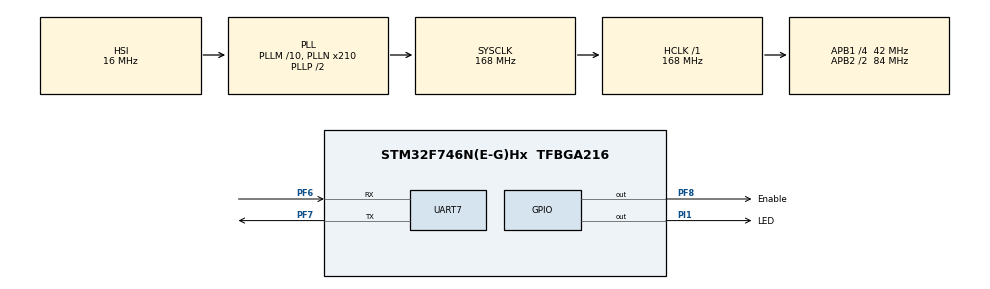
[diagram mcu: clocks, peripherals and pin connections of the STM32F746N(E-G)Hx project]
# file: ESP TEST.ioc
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Mcu.Family=STM32F7
Mcu.Name=STM32F746N(E-G)Hx
Mcu.Package=TFBGA216
NVIC.PriorityGroup=NVIC_PRIORITYGROUP_4
PF6.Mode=Asynchronous
PF6.Signal=UART7_RX
PF7.Mode=Asynchronous
PF7.Signal=UART7_TX
PF8.GPIO_Label=Enable
PF8.Signal=GPIO_Output
PI1.GPIO_Label=LED
PI1.Signal=GPIO_Output
ProjectManager.HeapSize=0x200
ProjectManager.StackSize=0x400
ProjectManager.TargetToolchain=SW4STM32
RCC.AHBFreq_Value=168000000
RCC.APB1CLKDivider=RCC_HCLK_DIV4
RCC.APB1Freq_Value=42000000
RCC.APB1TimFreq_Value=84000000
RCC.APB2CLKDivider=RCC_HCLK_DIV2
RCC.APB2Freq_Value=84000000
RCC.APB2TimFreq_Value=168000000
RCC.CortexFreq_Value=168000000
RCC.HCLKFreq_Value=168000000
RCC.HSE_VALUE=25000000
RCC.HSI_VALUE=16000000
RCC.LSE_VALUE=32768
RCC.PLLM=10
RCC.PLLN=210
RCC.PLLSourceVirtual=RCC_PLLSOURCE_HSI
RCC.SYSCLKFreq_VALUE=168000000
RCC.SYSCLKSource=RCC_SYSCLKSOURCE_PLLCLK
RCC.USBFreq_Value=168000000
RCC.VCOOutputFreq_Value=336000000
UART7.WordLength=UART_WORDLENGTH_8B
board=STM32F746G-DISCO

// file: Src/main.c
/**
  ******************************************************************************
  * File Name          : main.c
  * Description        : Main program body
  ******************************************************************************
  *
  * COPYRIGHT(c) 2016 STMicroelectronics
  *
  * Redistribution and use in source and binary forms, with or without modification,
  * are permitted provided that the following conditions are met:
  *   1. Redistributions of source code must retain the above copyright notice,
  *      this list of conditions and the following disclaimer.
  *   2. Redistributions in binary form must reproduce the above copyright notice,
  *      this list of conditions and the following disclaimer in the documentation
  *      and/or other materials provided with the distribution.
  *   3. Neither the name of STMicroelectronics nor the names of its contributors
  *      may be used to endorse or promote products derived from this software
  *      without specific prior written permission.
  *
  * THIS SOFTWARE IS PROVIDED BY THE COPYRIGHT HOLDERS AND CONTRIBUTORS "AS IS"
  * AND ANY EXPRESS OR IMPLIED WARRANTIES, INCLUDING, BUT NOT LIMITED TO, THE
  * IMPLIED WARRANTIES OF MERCHANTABILITY AND FITNESS FOR A PARTICULAR PURPOSE ARE
  * DISCLAIMED. IN NO EVENT SHALL THE COPYRIGHT HOLDER OR CONTRIBUTORS BE LIABLE
  * FOR ANY DIRECT, INDIRECT, INCIDENTAL, SPECIAL, EXEMPLARY, OR CONSEQUENTIAL
  * DAMAGES (INCLUDING, BUT NOT LIMITED TO, PROCUREMENT OF SUBSTITUTE GOODS OR
  * SERVICES; LOSS OF USE, DATA, OR PROFITS; OR BUSINESS INTERRUPTION) HOWEVER
  * CAUSED AND ON ANY THEORY OF LIABILITY, WHETHER IN CONTRACT, STRICT LIABILITY,
  * OR TORT (INCLUDING NEGLIGENCE OR OTHERWISE) ARISING IN ANY WAY OUT OF THE USE
  * OF THIS SOFTWARE, EVEN IF ADVISED OF THE POSSIBILITY OF SUCH DAMAGE.
  *
  ******************************************************************************
  */
#include "stm32f7xx_hal.h"

UART_HandleTypeDef huart7;

/* USER CODE BEGIN PV */
/* Private variables ---------------------------------------------------------*/

/* USER CODE END PV */

void SystemClock_Config(void);
void Error_Handler(void);
static void MX_GPIO_Init(void);
static void MX_UART7_Init(void);

/* USER CODE BEGIN PFP */
/* Private function prototypes -----------------------------------------------*/

/* USER CODE END PFP */

/* USER CODE BEGIN 0 */
void vActivety ( void );
void vEnableModulle( void );
void vDisableModulle ( void );
void  vTestModule ( void );
/* USER CODE END 0 */

int main(void)
{

  /* MCU Configuration----------------------------------------------------------*/

  /* Reset of all peripherals, Initializes the Flash interface and the Systick. */
  HAL_Init();

  /* Configure the system clock */
  SystemClock_Config();

  /* Initialize all configured peripherals */
  MX_GPIO_Init();
  MX_UART7_Init();

  /* Infinite loop */
  while (1)
  {

  }

}

/** System Clock Configuration
*/
void SystemClock_Config(void)
{

  RCC_OscInitTypeDef RCC_OscInitStruct;
  RCC_ClkInitTypeDef RCC_ClkInitStruct;
  RCC_PeriphCLKInitTypeDef PeriphClkInitStruct;

  __HAL_RCC_PWR_CLK_ENABLE();

  __HAL_PWR_VOLTAGESCALING_CONFIG(PWR_REGULATOR_VOLTAGE_SCALE2);

  RCC_OscInitStruct.OscillatorType = RCC_OSCILLATORTYPE_HSI;
  RCC_OscInitStruct.HSIState = RCC_HSI_ON;
  RCC_OscInitStruct.HSICalibrationValue = 16;
  RCC_OscInitStruct.PLL.PLLState = RCC_PLL_ON;
  RCC_OscInitStruct.PLL.PLLSource = RCC_PLLSOURCE_HSI;
  RCC_OscInitStruct.PLL.PLLM = 10;
  RCC_OscInitStruct.PLL.PLLN = 210;
  RCC_OscInitStruct.PLL.PLLP = RCC_PLLP_DIV2;
  RCC_OscInitStruct.PLL.PLLQ = 2;
  if (HAL_RCC_OscConfig(&RCC_OscInitStruct) != HAL_OK)
  {
    Error_Handler();
  }

  RCC_ClkInitStruct.ClockType = RCC_CLOCKTYPE_HCLK|RCC_CLOCKTYPE_SYSCLK
                              |RCC_CLOCKTYPE_PCLK1|RCC_CLOCKTYPE_PCLK2;
  RCC_ClkInitStruct.SYSCLKSource = RCC_SYSCLKSOURCE_PLLCLK;
  RCC_ClkInitStruct.AHBCLKDivider = RCC_SYSCLK_DIV1;
  RCC_ClkInitStruct.APB1CLKDivider = RCC_HCLK_DIV4;
  RCC_ClkInitStruct.APB2CLKDivider = RCC_HCLK_DIV2;
  if (HAL_RCC_ClockConfig(&RCC_ClkInitStruct, FLASH_LATENCY_5) != HAL_OK)
  {
    Error_Handler();
  }

  PeriphClkInitStruct.PeriphClockSelection = RCC_PERIPHCLK_UART7;
  PeriphClkInitStruct.Uart7ClockSelection = RCC_UART7CLKSOURCE_PCLK1;
  if (HAL_RCCEx_PeriphCLKConfig(&PeriphClkInitStruct) != HAL_OK)
  {
    Error_Handler();
  }

  HAL_SYSTICK_Config(HAL_RCC_GetHCLKFreq()/1000);

  HAL_SYSTICK_CLKSourceConfig(SYSTICK_CLKSOURCE_HCLK);

  /* SysTick_IRQn interrupt configuration */
  HAL_NVIC_SetPriority(SysTick_IRQn, 0, 0);
}

/* UART7 init function */
static void MX_UART7_Init(void)
{

  huart7.Instance = UART7;
  huart7.Init.BaudRate = 115200;
  huart7.Init.WordLength = UART_WORDLENGTH_8B;
  huart7.Init.StopBits = UART_STOPBITS_1;
  huart7.Init.Parity = UART_PARITY_NONE;
  huart7.Init.Mode = UART_MODE_TX_RX;
  huart7.Init.HwFlowCtl = UART_HWCONTROL_NONE;
  huart7.Init.OverSampling = UART_OVERSAMPLING_16;
  huart7.Init.OneBitSampling = UART_ONE_BIT_SAMPLE_DISABLE;
  huart7.AdvancedInit.AdvFeatureInit = UART_ADVFEATURE_NO_INIT;
  if (HAL_UART_Init(&huart7) != HAL_OK)
  {
    Error_Handler();
  }

}

/** Configure pins as
        * Analog
        * Input
        * Output
        * EVENT_OUT
        * EXTI
*/
static void MX_GPIO_Init(void)
{

  GPIO_InitTypeDef GPIO_InitStruct;

  /* GPIO Ports Clock Enable */
  __HAL_RCC_GPIOI_CLK_ENABLE();
  __HAL_RCC_GPIOF_CLK_ENABLE();

  /*Configure GPIO pin Output Level */
  HAL_GPIO_WritePin(LED_GPIO_Port, LED_Pin, GPIO_PIN_RESET);

  /*Configure GPIO pin Output Level */
  HAL_GPIO_WritePin(Enable_GPIO_Port, Enable_Pin, GPIO_PIN_RESET);

  /*Configure GPIO pin : LED_Pin */
  GPIO_InitStruct.Pin = LED_Pin;
  GPIO_InitStruct.Mode = GPIO_MODE_OUTPUT_PP;
  GPIO_InitStruct.Pull = GPIO_NOPULL;
  GPIO_InitStruct.Speed = GPIO_SPEED_FREQ_LOW;
  HAL_GPIO_Init(LED_GPIO_Port, &GPIO_InitStruct);

  /*Configure GPIO pin : Enable_Pin */
  GPIO_InitStruct.Pin = Enable_Pin;
  GPIO_InitStruct.Mode = GPIO_MODE_OUTPUT_PP;
  GPIO_InitStruct.Pull = GPIO_NOPULL;
  GPIO_InitStruct.Speed = GPIO_SPEED_FREQ_LOW;
  HAL_GPIO_Init(Enable_GPIO_Port, &GPIO_InitStruct);

}

/* USER CODE BEGIN 4 */
void vActivety ( void )
{
	HAL_GPIO_WritePin(LED_GPIO_Port , LED_Pin , GPIO_PIN_SET  );
	HAL_Delay(1000);
	HAL_GPIO_WritePin(LED_GPIO_Port , LED_Pin , GPIO_PIN_RESET  );
	HAL_Delay(1000);
}

void vEnableModule( void )
{
	HAL_GPIO_WritePin( Enable_GPIO_Port , Enable_Pin , GPIO_PIN_SET);
}

void vDisableModulle( void )
{
	HAL_GPIO_WritePin( Enable_GPIO_Port , Enable_Pin , GPIO_PIN_RESET);
}

void vTestModulle ( void )
{

}
	/* USER CODE END 4 */

void Error_Handler(void)
{
  while(1)
  {
  }
}

/************************ (C) COPYRIGHT STMicroelectronics *****END OF FILE****/
